AUTOSAR XML (schema 00044)
package /E40_Platform_System_SystemPackage/Components
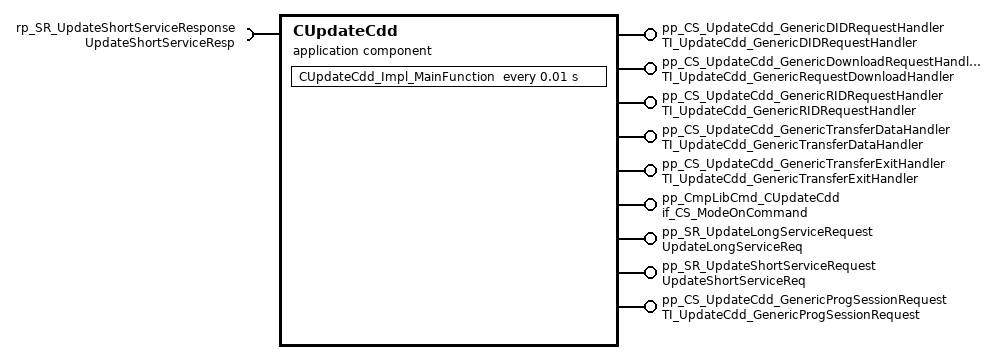
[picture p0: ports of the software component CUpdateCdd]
  application sw component type CUpdateCdd
    8 x provide port:
      pp_CS_UpdateCdd_GenericDIDRequestHandler: server-com-spec{operation=UpdateCdd_GenericDIDRequestHandler, queue-length=1}, provided-interface=TI_UpdateCdd_GenericDIDRequestHandler
      pp_CS_UpdateCdd_GenericDownloadRequestHandler: server-com-spec{operation=UpdateCdd_GenericRequestDownloadHandler, queue-length=1}, provided-interface=TI_UpdateCdd_GenericRequestDownloadHandler
      pp_CS_UpdateCdd_GenericRIDRequestHandler: server-com-spec{operation=UpdateCdd_GenericRIDRequestHandler, queue-length=1}, provided-interface=TI_UpdateCdd_GenericRIDRequestHandler
      pp_CS_UpdateCdd_GenericTransferDataHandler: server-com-spec{operation=UpdateCdd_GenericTransferDataHandler, queue-length=1}, provided-interface=TI_UpdateCdd_GenericTransferDataHandler
      pp_CS_UpdateCdd_GenericTransferExitHandler: server-com-spec{operation=UpdateCdd_GenericTransferExitHandler, queue-length=1}, provided-interface=TI_UpdateCdd_GenericTransferExitHandler
      pp_CmpLibCmd_CUpdateCdd: server-com-spec{operation=Impl_OnCommand, queue-length=1}, provided-interface=if_CS_ModeOnCommand
      pp_SR_UpdateLongServiceRequest: provided-interface=UpdateLongServiceReq
        provided-com-specs:
          nonqueued-sender-com-spec=init-value=constant-reference=CUpdateCddUpdateLongServiceReqValue0
          queued-sender-com-spec=UpdateLongServiceReqData
      pp_SR_UpdateShortServiceRequest: provided-interface=UpdateShortServiceReq
        provided-com-specs:
          nonqueued-sender-com-spec=init-value=constant-reference=CUpdateCddUpdateShortServiceReqValue0
          queued-sender-com-spec=UpdateShortServiceReqData
    require port rp_SR_UpdateShortServiceResponse: required-interface=UpdateShortServiceResp
      required-com-specs:
        nonqueued-receiver-com-spec=init-value=constant-reference=CUpdateCddUpdateShortServiceRespValue0
        queued-receiver-com-spec={data-element=UpdateShortServiceRespData, queue-length=2}
    provide port pp_CS_UpdateCdd_GenericProgSessionRequest: server-com-spec{operation=UpdateCdd_GenericProgSessionRequest, queue-length=1}, provided-interface=TI_UpdateCdd_GenericProgSessionRequest
    behavior IB_CUpdateCdd
      timing event TECUpdateCdd_Impl_MainFunction: start-on-event=CUpdateCdd_Impl_MainFunction, period=0.01
      operation invoked event OIE_pp_CmpLibCmd_CUpdateCdd_CUpdateCdd_Impl_OnCommandTrigByImpl_OnCommand: start-on-event=CUpdateCdd_Impl_OnCommand, operation=pp_CmpLibCmd_CUpdateCdd.Impl_OnCommand
      operation invoked event OperationInvokeEvent_105: start-on-event=CUpdateCdd_UpdateCdd_GenericDIDRequestHandler, operation=pp_CS_UpdateCdd_GenericDIDRequestHandler.UpdateCdd_GenericDIDRequestHandler
      data received event DRECUpdateCdd_OnDre_UpdateResponseTrigByUpdateShortServiceRespData: start-on-event=CUpdateCdd_OnDre_UpdateResponse, data=rp_SR_UpdateShortServiceResponse.UpdateShortServiceRespData
      5 x operation invoked event:
        OperationInvokeEvent_106: start-on-event=CUpdateCdd_UpdateCdd_GenericProgSessionRequest, operation=pp_CS_UpdateCdd_GenericProgSessionRequest.UpdateCdd_GenericProgSessionRequest
        OperationInvokeEvent_107: start-on-event=CUpdateCdd_UpdateCdd_GenericRIDRequestHandler, operation=pp_CS_UpdateCdd_GenericRIDRequestHandler.UpdateCdd_GenericRIDRequestHandler
        OperationInvokeEvent_108: start-on-event=CUpdateCdd_UpdateCdd_GenericRequestDownloadHandler, operation=pp_CS_UpdateCdd_GenericDownloadRequestHandler.UpdateCdd_GenericRequestDownloadHandler
        OperationInvokeEvent_109: start-on-event=CUpdateCdd_UpdateCdd_GenericTransferDataHandler, operation=pp_CS_UpdateCdd_GenericTransferDataHandler.UpdateCdd_GenericTransferDataHandler
        OperationInvokeEvent_110: start-on-event=CUpdateCdd_UpdateCdd_GenericTransferExitHandler, operation=pp_CS_UpdateCdd_GenericTransferExitHandler.UpdateCdd_GenericTransferExitHandler
      port-api-options:
        enable-take-address=false, indirect-api=false, port=pp_CS_UpdateCdd_GenericDIDRequestHandler
        enable-take-address=false, indirect-api=false, port=pp_CS_UpdateCdd_GenericDownloadRequestHandler
        enable-take-address=false, indirect-api=false, port=pp_CS_UpdateCdd_GenericRIDRequestHandler
        enable-take-address=false, indirect-api=false, port=pp_CS_UpdateCdd_GenericTransferDataHandler
        enable-take-address=false, indirect-api=false, port=pp_CS_UpdateCdd_GenericTransferExitHandler
        enable-take-address=false, indirect-api=false, port=pp_CmpLibCmd_CUpdateCdd
        enable-take-address=false, indirect-api=false, port=pp_SR_UpdateLongServiceRequest
        enable-take-address=false, indirect-api=false, port=pp_SR_UpdateShortServiceRequest
        enable-take-address=false, indirect-api=false, port=rp_SR_UpdateShortServiceResponse
        enable-take-address=false, indirect-api=false, port=pp_CS_UpdateCdd_GenericProgSessionRequest
      9 x runnable, all with can-be-invoked-concurrently=true:
        CUpdateCdd_Impl_MainFunction
          data-receive-point-by-arguments:
            access DRP_rp_SR_UpdateShortServiceResponse_UpdateShortServiceRespData: accessed-variable=rp_SR_UpdateShortServiceResponse.UpdateShortServiceRespData
          data-send-points:
            access DSP_pp_SR_UpdateLongServiceRequest_UpdateLongServiceReqData: accessed-variable=pp_SR_UpdateLongServiceRequest.UpdateLongServiceReqData
            access DSP_pp_SR_UpdateShortServiceRequest_UpdateShortServiceReqData: accessed-variable=pp_SR_UpdateShortServiceRequest.UpdateShortServiceReqData
        CUpdateCdd_Impl_OnCommand
          data-receive-point-by-arguments:
            access DRP_rp_SR_UpdateShortServiceResponse_UpdateShortServiceRespData: accessed-variable=rp_SR_UpdateShortServiceResponse.UpdateShortServiceRespData
          data-send-points:
            access DSP_pp_SR_UpdateLongServiceRequest_UpdateLongServiceReqData: accessed-variable=pp_SR_UpdateLongServiceRequest.UpdateLongServiceReqData
            access DSP_pp_SR_UpdateShortServiceRequest_UpdateShortServiceReqData: accessed-variable=pp_SR_UpdateShortServiceRequest.UpdateShortServiceReqData
        CUpdateCdd_UpdateCdd_GenericDIDRequestHandler
          data-receive-point-by-arguments:
            access DRP_rp_SR_UpdateShortServiceResponse_UpdateShortServiceRespData: accessed-variable=rp_SR_UpdateShortServiceResponse.UpdateShortServiceRespData
          data-send-points:
            access DSP_pp_SR_UpdateLongServiceRequest_UpdateLongServiceReqData: accessed-variable=pp_SR_UpdateLongServiceRequest.UpdateLongServiceReqData
            access DSP_pp_SR_UpdateShortServiceRequest_UpdateShortServiceReqData: accessed-variable=pp_SR_UpdateShortServiceRequest.UpdateShortServiceReqData
        CUpdateCdd_UpdateCdd_GenericRIDRequestHandler
          data-receive-point-by-arguments:
            access DRP_rp_SR_UpdateShortServiceResponse_UpdateShortServiceRespData: accessed-variable=rp_SR_UpdateShortServiceResponse.UpdateShortServiceRespData
          data-send-points:
            access DSP_pp_SR_UpdateLongServiceRequest_UpdateLongServiceReqData: accessed-variable=pp_SR_UpdateLongServiceRequest.UpdateLongServiceReqData
            access DSP_pp_SR_UpdateShortServiceRequest_UpdateShortServiceReqData: accessed-variable=pp_SR_UpdateShortServiceRequest.UpdateShortServiceReqData
        CUpdateCdd_UpdateCdd_GenericTransferDataHandler
          data-receive-point-by-arguments:
            access DRP_rp_SR_UpdateShortServiceResponse_UpdateShortServiceRespData: accessed-variable=rp_SR_UpdateShortServiceResponse.UpdateShortServiceRespData
          data-send-points:
            access DSP_pp_SR_UpdateLongServiceRequest_UpdateLongServiceReqData: accessed-variable=pp_SR_UpdateLongServiceRequest.UpdateLongServiceReqData
            access DSP_pp_SR_UpdateShortServiceRequest_UpdateShortServiceReqData: accessed-variable=pp_SR_UpdateShortServiceRequest.UpdateShortServiceReqData
        CUpdateCdd_UpdateCdd_GenericTransferExitHandler
          data-receive-point-by-arguments:
            access DRP_rp_SR_UpdateShortServiceResponse_UpdateShortServiceRespData: accessed-variable=rp_SR_UpdateShortServiceResponse.UpdateShortServiceRespData
          data-send-points:
            access DSP_pp_SR_UpdateLongServiceRequest_UpdateLongServiceReqData: accessed-variable=pp_SR_UpdateLongServiceRequest.UpdateLongServiceReqData
            access DSP_pp_SR_UpdateShortServiceRequest_UpdateShortServiceReqData: accessed-variable=pp_SR_UpdateShortServiceRequest.UpdateShortServiceReqData
        CUpdateCdd_OnDre_UpdateResponse
          data-receive-point-by-arguments:
            access DRP_rp_SR_UpdateShortServiceResponse_UpdateShortServiceRespData: accessed-variable=rp_SR_UpdateShortServiceResponse.UpdateShortServiceRespData
          data-send-points:
            access DSP_pp_SR_UpdateLongServiceRequest_UpdateLongServiceReqData: accessed-variable=pp_SR_UpdateLongServiceRequest.UpdateLongServiceReqData
            access DSP_pp_SR_UpdateShortServiceRequest_UpdateShortServiceReqData: accessed-variable=pp_SR_UpdateShortServiceRequest.UpdateShortServiceReqData
        CUpdateCdd_UpdateCdd_GenericRequestDownloadHandler
          data-receive-point-by-arguments:
            access DRP_rp_SR_UpdateShortServiceResponse_UpdateShortServiceRespData: accessed-variable=rp_SR_UpdateShortServiceResponse.UpdateShortServiceRespData
          data-send-points:
            access DSP_pp_SR_UpdateLongServiceRequest_UpdateLongServiceReqData: accessed-variable=pp_SR_UpdateLongServiceRequest.UpdateLongServiceReqData
            access DSP_pp_SR_UpdateShortServiceRequest_UpdateShortServiceReqData: accessed-variable=pp_SR_UpdateShortServiceRequest.UpdateShortServiceReqData
        CUpdateCdd_UpdateCdd_GenericProgSessionRequest
          data-receive-point-by-arguments:
            access DRP_rp_SR_UpdateShortServiceResponse_UpdateShortServiceRespData: accessed-variable=rp_SR_UpdateShortServiceResponse.UpdateShortServiceRespData
          data-send-points:
            access DSP_pp_SR_UpdateLongServiceRequest_UpdateLongServiceReqData: accessed-variable=pp_SR_UpdateLongServiceRequest.UpdateLongServiceReqData
            access DSP_pp_SR_UpdateShortServiceRequest_UpdateShortServiceReqData: accessed-variable=pp_SR_UpdateShortServiceRequest.UpdateShortServiceReqData
  swc implementation IMPL_CUpdateCdd: behavior=IB_CUpdateCdd
